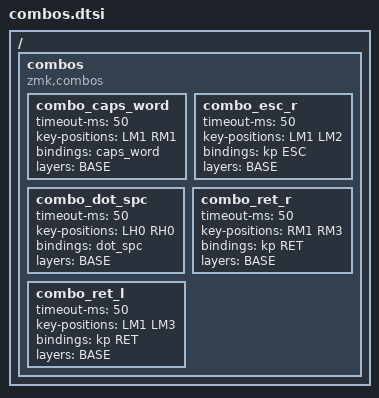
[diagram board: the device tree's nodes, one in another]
/ {
  combos {
    compatible = "zmk,combos";

    combo_caps_word {
      timeout-ms = <50>;
      key-positions = <LM1 RM1>;
      bindings = <&caps_word>;
      layers = <BASE>;
    };

    combo_esc_r {
      timeout-ms = <50>;
      key-positions = <RM1 RM2>;
      bindings = <&kp ESC>;
      layers = <BASE>;
    };

    combo_esc_r {
      timeout-ms = <50>;
      key-positions = <LM1 LM2>;
      bindings = <&kp ESC>;
      layers = <BASE>;
    };

    combo_dot_spc {
      timeout-ms = <50>;
      key-positions = <LH0 RH0>;
      bindings = <&dot_spc>;
      layers = <BASE>;
    };

    combo_ret_r {
      timeout-ms = <50>;
      key-positions = <RM1 RM3>;
      bindings = <&kp RET>;
      layers = <BASE>;
    };

    combo_ret_l {
      timeout-ms = <50>;
      key-positions = <LM1 LM3>;
      bindings = <&kp RET>;
      layers = <BASE>;
    };
  };
};

